# ATmega2564RFR2 device description
Architecture: AVR8; Family: megaAVR
Registers are 8-bit, access not given, no defined reset value unless marked. A register's access mark holds for its fields unless they carry their own. Offsets are from the block's base; [hi:lo] are bit positions.

## FUSE — Fuses
Instances: FUSE 0 in fuses
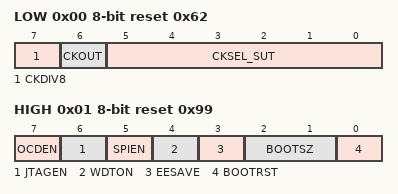
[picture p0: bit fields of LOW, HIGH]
0x00 LOW reset 0x62
  [7] CKDIV8 — Divide clock by 8 internally
  [6] CKOUT — Clock output on PORTE7
  [5:0] CKSEL_SUT — Select Clock Source : Start-up time
    0=EXTCLK_6CK_0MS (Ext. Clock; Start-up time: 6 CK + 0 ms); 16=EXTCLK_6CK_4MS1 (Ext. Clock; Start-up time: 6 CK + 4.1 ms); 32=EXTCLK_6CK_65MS (Ext. Clock; Start-up time: 6 CK + 65 ms); 2=INTRCOSC_6CK_0MS (Int. RC Osc.; Start-up time: 6 CK + 0 ms); 18=INTRCOSC_6CK_4MS1 (Int. RC Osc.; Start-up time: 6 CK + 4.1 ms); 34=INTRCOSC_6CK_65MS (Int. RC Osc.; Start-up time: 6 CK + 65 ms); 3=INTRCOSC_128KHZ_6CK_0MS (Int. 128kHz RC Osc.; Start-up time: 6 CK + 0 ms); 19=INTRCOSC_128KHZ_6CK_4MS1 (Int. 128kHz RC Osc.; Start-up time: 6 CK + 4.1 ms); 35=INTRCOSC_128KHZ_6CK_65MS (Int. 128kHz RC Osc.; Start-up time: 6 CK + 65 ms); 6=TOSC_258CK_4MS1 (Tranceiver Oscillator; Start-up time: 258 CK + 4.1 ms); 22=TOSC_258CK_65MS (Tranceiver Oscillator; Start-up time: 258 CK + 65 ms); 38=TOSC_1KCK_0MS (Tranceiver Oscillator; Start-up time: 1K CK + 0 ms); 54=TOSC_1KCK_4MS1 (Tranceiver Oscillator; Start-up time: 1K CK + 4.1 ms); 7=TOSC_1KCK_65MS (Tranceiver Oscillator; Start-up time: 1K CK + 65 ms); 23=TOSC_16KCK_0MS (Tranceiver Oscillator; Start-up time: 16K CK + 0 ms); 39=TOSC_16KCK_4MS1 (Tranceiver Oscillator; Start-up time: 16K CK + 4.1 ms); 55=TOSC_16KCK_65MS (Tranceiver Oscillator; Start-up time: 16K CK + 65 ms); 8=TOSC_258CK_4MS1 (Tranceiver Oscillator; Start-up time: 258 CK + 4.1 ms); 24=TOSC_258CK_65MS (Tranceiver Oscillator; Start-up time: 258 CK + 65 ms); 40=TOSC_1KCK_0MS (Tranceiver Oscillator; Start-up time: 1K CK + 0 ms); 56=TOSC_1KCK_4MS1 (Tranceiver Oscillator; Start-up time: 1K CK + 4.1 ms); 9=TOSC_1KCK_65MS (Tranceiver Oscillator; Start-up time: 1K CK + 65 ms); 25=TOSC_16KCK_0MS (Tranceiver Oscillator; Start-up time: 16K CK + 0 ms); 41=TOSC_16KCK_4MS1 (Tranceiver Oscillator; Start-up time: 16K CK + 4.1 ms); 57=TOSC_16KCK_65MS (Tranceiver Oscillator; Start-up time: 16K CK + 65 ms); 10=TOSC_258CK_4MS1 (Tranceiver Oscillator; Start-up time: 258 CK + 4.1 ms); 26=TOSC_258CK_65MS (Tranceiver Oscillator; Start-up time: 258 CK + 65 ms); 42=TOSC_1KCK_0MS (Tranceiver Oscillator; Start-up time: 1K CK + 0 ms); 58=TOSC_1KCK_4MS1 (Tranceiver Oscillator; Start-up time: 1K CK + 4.1 ms); 11=TOSC_1KCK_65MS (Tranceiver Oscillator; Start-up time: 1K CK + 65 ms); 27=TOSC_16KCK_0MS (Tranceiver Oscillator; Start-up time: 16K CK + 0 ms); 43=TOSC_16KCK_4MS1 (Tranceiver Oscillator; Start-up time: 16K CK + 4.1 ms); 59=TOSC_16KCK_65MS (Tranceiver Oscillator; Start-up time: 16K CK + 65 ms); 12=TOSC_258CK_4MS1 (Tranceiver Oscillator; Start-up time: 258 CK + 4.1 ms); 28=TOSC_258CK_65MS (Tranceiver Oscillator; Start-up time: 258 CK + 65 ms); 44=TOSC_1KCK_0MS (Tranceiver Oscillator; Start-up time: 1K CK + 0 ms); 60=TOSC_1KCK_4MS1 (Tranceiver Oscillator; Start-up time: 1K CK + 4.1 ms); 13=TOSC_1KCK_65MS (Tranceiver Oscillator; Start-up time: 1K CK + 65 ms); 29=TOSC_16KCK_0MS (Tranceiver Oscillator; Start-up time: 16K CK + 0 ms); 45=TOSC_16KCK_4MS1 (Tranceiver Oscillator; Start-up time: 16K CK + 4.1 ms); 61=TOSC_16KCK_65MS (Tranceiver Oscillator; Start-up time: 16K CK + 65 ms); 14=TOSC_258CK_4MS1 (Tranceiver Oscillator; Start-up time: 258 CK + 4.1 ms); 30=TOSC_258CK_65MS (Tranceiver Oscillator; Start-up time: 258 CK + 65 ms); 46=TOSC_1KCK_0MS (Tranceiver Oscillator; Start-up time: 1K CK + 0 ms); 62=TOSC_1KCK_4MS1 (Tranceiver Oscillator; Start-up time: 1K CK + 4.1 ms); 15=TOSC_1KCK_65MS (Tranceiver Oscillator; Start-up time: 1K CK + 65 ms); 31=TOSC_16KCK_0MS (Tranceiver Oscillator; Start-up time: 16K CK + 0 ms); 47=TOSC_16KCK_4MS1 (Tranceiver Oscillator; Start-up time: 16K CK + 4.1 ms); 63=TOSC_16KCK_65MS (Tranceiver Oscillator; Start-up time: 16K CK + 65 ms)
0x01 HIGH reset 0x99
  [7] OCDEN — On-Chip Debug Enabled
  [6] JTAGEN — JTAG Interface Enabled
  [5] SPIEN — Serial program downloading (SPI) enabled
  [4] WDTON — Watchdog timer always on
  [3] EESAVE — Preserve EEPROM through the Chip Erase cycle
  [2:1] BOOTSZ — Select Boot Size
    3=512W_1FE00 (Boot Flash size=512 words start address=$1FE00); 2=1024W_1FC00 (Boot Flash size=1024 words start address=$1FC00); 1=2048W_1F800 (Boot Flash size=2048 words start address=$1F800); 0=4096W_1F000 (Boot Flash size=4096 words start address=$1F000)
  [0] BOOTRST — Boot Reset vector Enabled
0x02 EXTENDED reset 0xFE
  [2:0] BODLEVEL — Brown-out Detector trigger level
    7=DISABLED (Brown-out detection disabled); 6=1V8 (Brown-out detection at VCC=1.8 V); 5=1V9 (Brown-out detection at VCC=1.9 V); 4=2V0 (Brown-out detection at VCC=2.0 V); 3=2V1 (Brown-out detection at VCC=2.1 V); 2=2V2 (Brown-out detection at VCC=2.2 V); 1=2V3 (Brown-out detection at VCC=2.3 V); 0=2V4 (Brown-out detection at VCC=2.4 V)
